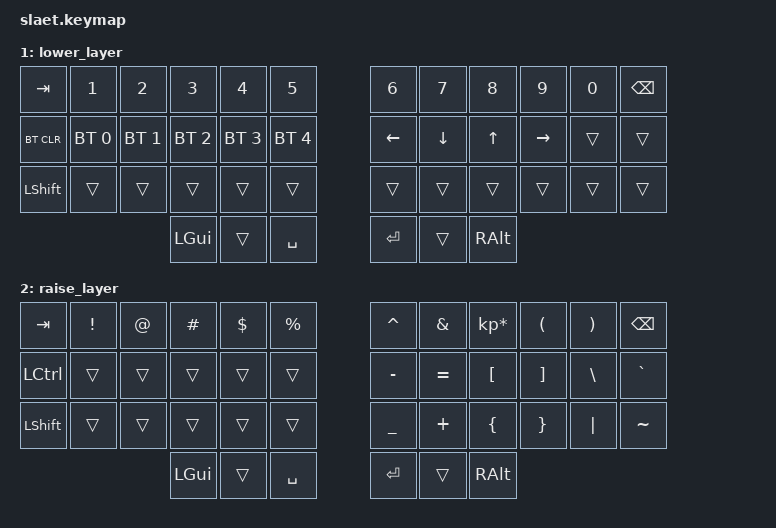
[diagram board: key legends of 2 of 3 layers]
#include <behaviors.dtsi>
#include <dt-bindings/zmk/keys.h>
#include <dt-bindings/zmk/bt.h>

//  ╭────────────────────╮ ╭────────────────────╮
//  │  0   1   2   3   4 │ │  5   6   7   8   9 │
//  │ 10  11  12  13  14 │ │ 15  16  17  18  19 │
//  │ 20  21  22  23  24 │ │ 25  26  27  28  29 │
//  ╰───────╮ 30  31 32  │ │ 33  34  35 ╭───────╯
//          ╰────────────╯ ╰────────────╯           

/ {
        keymap {
                compatible = "zmk,keymap";

                default_layer {

                        bindings = <
   &kp TAB   &kp Q &kp W &kp F &kp P &kp G   &kp J &kp L  &kp U     &kp Y   &kp ;    &kp BSPC
   &kp LCTRL &kp A &kp R &kp S &kp T &kp D   &kp H &kp N  &kp E     &kp I   &kp O &kp SQT
   &kp LSHFT &kp Z &kp X &kp C &kp V &kp B   &kp K &kp M  &kp COMMA &kp DOT &kp FSLH &kp ESC
                  &kp LGUI &sk LSHIFT &kp SPACE   &kp RET &mo 2 &kp RALT
                        >;
                };
                lower_layer {

                        bindings = <
   &kp TAB    &kp N1       &kp N2       &kp N3       &kp N4       &kp N5         &kp N6   &kp N7   &kp N8 &kp N9    &kp N0 &kp BSPC
   &bt BT_CLR &bt BT_SEL 0 &bt BT_SEL 1 &bt BT_SEL 2 &bt BT_SEL 3 &bt BT_SEL 4   &kp LEFT &kp DOWN &kp UP &kp RIGHT &trans &trans
   &kp LSHFT  &trans       &trans       &trans       &trans       &trans         &trans   &trans   &trans &trans    &trans &trans
                                    &kp LGUI     &trans       &kp SPACE      &kp RET  &trans   &kp RALT
                        >;
                };

                raise_layer {

                        bindings = <
   &kp  TAB  &kp EXCL &kp AT &kp HASH &kp DLLR &kp PRCNT   &kp CARET &kp AMPS  &kp KP_MULTIPLY &kp LPAR &kp RPAR &kp BSPC
   &kp LCTRL &trans   &trans &trans   &trans   &trans      &kp MINUS &kp EQUAL &kp LBKT        &kp RBKT &kp BSLH &kp GRAVE
   &kp LSHFT &trans   &trans &trans   &trans   &trans      &kp UNDER &kp PLUS  &kp LBRC        &kp RBRC &kp PIPE &kp TILDE
                             &kp LGUI &trans   &kp SPACE   &kp RET   &trans    &kp RALT
                        >;
                };
        };
};
